# CCG2 register map
File version: 1.0
CPU: CM0 r1p0, little endian, no MPU, no FPU, 2 interrupt priority bits
Registers are 32-bit, read-write, reset 0x0 unless marked. A register's access mark holds for its fields unless they carry their own. Offsets are from the block's base; [hi:lo] are bit positions; <NAME> marks a mode.

## SCB0 (part 1 of 2)
Base 0x40050000
Same registers: SCB1 0x40060000
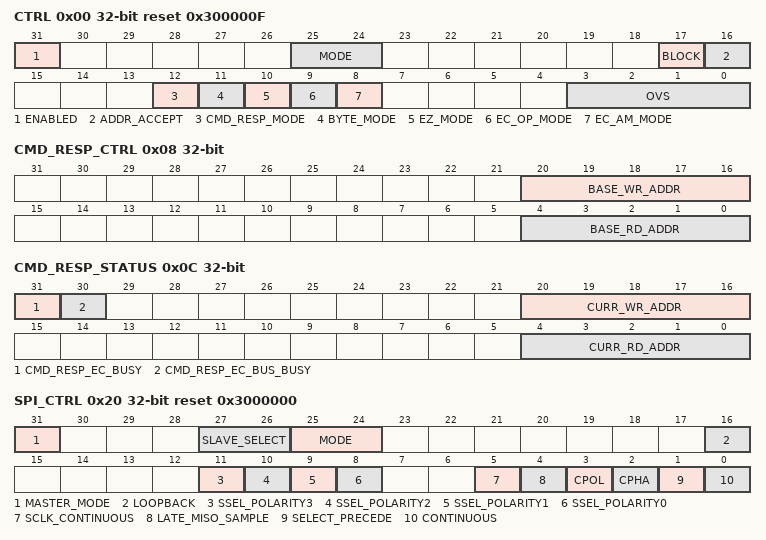
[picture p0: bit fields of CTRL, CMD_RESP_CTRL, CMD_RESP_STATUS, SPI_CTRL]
0x00 CTRL reset 0x300000F — Generic control register.
  [31] ENABLED — IP enabled ('1') or not ('0'). The proper order in which to initialize the IP is as follows: - Program protocol specific information using SPI_CTRL, UART_CTRL (and UART_TX_CTRL and UART_RX_CTRL) or I2C_CTRL. This includes selection of a submode, master/slave functionality and transmitter/receiver functionality when applicable. - Program generic transmitter (TX_CTRL) and receiver (RX_CTRL) information. This includes enabling of the transmitter and receiver functionality. - Program transmitter FIFO (TX_FIFO_CTRL) and receiver FIFO (RX_FIFO_CTRL) information. - Program CTRL to enable IP, select the specific operation mode and oversampling factor. When the IP is enabled, no control information should be changed. Changes should be made AFTER disabling the IP, e.g. to modify the operation mode (from I2C to SPI) or to go from externally to internally clocked. The change takes effect after the IP is re-enabled. Note that disabling the IP will cause re-initialization of the design and associated state is lost (e.g. FIFO content).
  [25:24] MODE — Mode of operation (3: Reserved)
    0=I2C; 1=SPI; 2=UART
  [17] BLOCK — Only used in externally clocked mode. If the externally clocked logic and the MMIO SW accesses to EZ memory coincide/collide, this bit determines whether a SW access should block and result in bus wait states ('BLOCK is 1') or not (BLOCK is '0'). IF BLOCK is �0� and the accesses collide, MMIO read operations return 0xffff:ffff and MMIO write operations are ignored. Colliding accesses are registered as interrupt causes: field BLOCKED of MMIO registers INTR_TX and INTR_RX.
  [16] ADDR_ACCEPT — Determines whether a received matching address is accepted in the RX FIFO ('1') or not ('0'). In I2C mode, this field is used to allow the slave to put the received slave address or general call address in the RX FIFO. Note that a received matching address is put in the RX FIFO when ADDR_ACCEPT is '1' for both I2C read and write transfers. In multi-processor UART receiver mode, this field is used to allow the receiver to put the received address in the RX FIFO. Note: non-matching addresses are never put in the RX FIFO.
  [12] CMD_RESP_MODE — Determines CMD_RESP mode of operation: '0': CMD_RESP mode disabled. '1': CMD_RESP mode enabled (also requires EC_AM_MODE and EC_OP_MODE to be set to '1').
  [11] BYTE_MODE — Determines the number of bits per FIFO data element: '0': 16-bit FIFO data elements. '1': 8-bit FIFO data elements. This mode doubles the amount of FIFO entries, but TX_CTRL.DATA_WIDTH and RX_CTRL.DATA_WIDTH are restricted to [0, 7].
  [10] EZ_MODE — Non EZ mode ('0') or EZ mode ('1'). In EZ mode, a meta protocol is applied to the serial interface protocol. This meta protocol adds meaning to the data frames transferred by the serial interface protocol: a data frame can represent a memory address, a write memory data element or a read memory data element. EZ mode is only used for synchronous serial interface protocols: SPI and I2C. In SPI mode, only Motorola submode (all Motorola modes: 0, 1, 2, 3) is supported and the transmitter should use continuous data frames; i.e. data frames mot seperated by slave deselection. This mode is only applicable to slave functionality. In EZ mode, the slave can read from and write to an addressable memory structure of 32 bytes. In EZ mode, data frames should 8-bit in size and should be transmitted and received with the Most Significant Bit (MSB) first. In UART mode this field should be '0'.
  [9] EC_OP_MODE — Internally clocked mode ('0') or externally clocked mode ('1') operation. In internally clocked mode, the serial interface protocols run off the peripheral clock. In externally clocked mode, the serial interface protocols run off the clock as provided by the serial interface. Externally clocked operation mode is only used for synchronous serial interface protocols (SPI and I2C) in slave mode AND EZ mode. In SPI mode, only Motorola submode (all Motorola modes: 0, 1, 2, 3) is supported. The maximum SPI slave, EZ mode bitrate is 48 Mbps (transmission and IO delays outside the IP will degrade the effective bitrate). In UART mode this field should be '0'.
  [8] EC_AM_MODE — Internally clocked mode ('0') or externally clocked mode ('1') address matching (I2C) or selection (SPI). In internally clocked mode, the serial interface protocols run off the peripheral clock. In externally clocked mode, the serial interface protocols run off the clock as provided by the serial interface. Externally clocked mode is only used for synchronous serial interface protocols (SPI and I2C) in slave mode. In SPI mode, only Motorola submode (all Motorola modes: 0, 1, 2, 3) is supported. In UART mode this field should be '0'.
  [3:0] OVS — Serial interface bit period oversampling factor expressed in lP clock cycles. Used for SPI and UART functionality. OVS + 1 IP clock cycles constitute a single serial interface clock/bit cycle. The IP clock is provided by the programmable clock IP. This field is NOT used in externally clocked mode. If OVS is odd, the oversampling factor is even and the first and second phase of the interface clock period are the same. If OVS is even, the oversampling factor is odd and the first phase of the interface clock period is 1 peripheral clock cycle longer than the second phase of the interface clock period. In SPI master mode, the valid range is [3, 15]. At an IP frequency of 48 MHz, the maximum IP bit rate is 12 Mbps. The effective system bit rate is dependent on the external SPI slave that we communicate with. If the SPI output clock "spi_clk_out" to SPI MISO input "spi_miso_in" round trip delay is introducing significant delays (multiple "spi_clk_out" cycles), it may be necessary to increase OVS and/or to set SPI_CTRL.LATE_MISO_SAMPLE to '1' to achieve the maximum possible system bit rate. The maximum IP bit rate of 12 Mbps provides an IP centric perspective, assuming ideal (0 ns) IO cell and routing (chip and board) delay. The required IP clock/IF clock ratio increases and the calculated maximum bit rate decreases, when realistic chip and routing delays are taken into account. In SPI slave mode, the OVS field is NOT used. However, there is a frequency requirement for the IP clock wrt. the interface (IF) clock to guarantee functional correct behavior. This requirement is expressed as a ratio: IP clock/IF clock. The ratio is dependent on the setting of RX_CTRL.MEDIAN and the external SPI master's capability to support "late MISO sample" functionality (similar to our SPI master functionality represented by SPI_CTRL.LATE_MISO_SAMPLE): - MEDIAN is '0' and external SPI master has NO "late MISO sample functionality": IP clock/IF clock >= 6. At a IP frequency of 48 MHz, the maximum bit rate is 8 Mbps. - MEDIAN is '0' and external SPI master has "late MISO sample functionality": IP clock/IF clock >= 3. At a IP frequency of 48 MHz, the maximum bit rate is 16 Mbps. - MEDIAN is '1' and external SPI master has NO "late MISO sample functionality": IP clock/IF clock >= 8. At a IP frequency of 48 MHz, the maximum bit rate is 6 Mbps. - MEDIAN is '1' and external SPI master has "late MISO sample functionality": IP clock/IF clock >= 4. At a IP frequency of 48 MHz, the maximum bit rate is 12 Mbps. The maximum bit rates provide an IP centric perspective, assuming ideal (0 ns) IO cell and routing (chip and board) delay. The required IP clock/IF clock ratio increases and the calculated maximum bit rate decreases, when realistic chip and routing delays are taken into account. In UART standard submode (including LIN), the valid range is [7, 15]. In UART SmartCard submode, the valid range is [7, 15]. In UART TX IrDA submode this field indirectly specifies the oversampling. The oversampling determines the interface clock/bit cycle and the width of the pulse. Only normal transmission mode is supported, the pulse is roughly 3/16 of the bit period (for all bit rates). There is only one valid OVS value: - 0: 16 times oversampling. IP clock frequency of 16*115.2 KHz for 115.2 Kbps. IP clock frequency of 16*57.6 KHz for 57.6 Kbps. IP clock frequency of 16*38.4 KHz for 38.4 Kbps. IP clock frequency of 16*19.2 KHz for 19.2 Kbps. IP clock frequency of 16*9.6 KHz for 9.6 Kbps. IP clock frequency of 16*2.4 KHz for 2.4 Kbps. IP clock frequency of 16*1.2 KHz for 1.2 Kbps. - all other values are not used in normal mode. In UART RX IrDA submode (1.2, 2.4, 9.6, 19.2, 38.4, 57.6 and 115.2 Kbps) this field indirectly specifies the oversampling. The oversampling determines the interface clock/bit cycle and the width of the pulse. In normal transmission mode, this pulse is roughly 3/16 of the bit period (for all bit rates). In low power transmission mode, this pulse is potentially smaller (down to 1.62 us typical and 1.41 us minimal) than 3/16 of the bit period (for < 115.2 Kbps bitrates). Pulse widths greater or equal than two IP clock cycles are guaranteed to be detected by the receiver. Pulse widths less than two IP clock cycles and greater or equal than one IP clock cycle may be detected by the receiver. Pulse widths less than one IP clock cycle will not be detected by the receiver. RX_CTRL.MEDIAN should be set to '1' for IrDA receiver functionality. The IP clock (as provided by the programmable clock IP) and the oversampling together determine the IrDA bitrate. Normal mode, OVS field values (with the required IP clock frequency): - 0: 16 times oversampling. IP clock frequency of 16*115.2 KHz for 115.2 Kbps. IP clock frequency of 16*57.6 KHz for 57.6 Kbps. IP clock frequency of 16*38.4 KHz for 38.4 Kbps. IP clock frequency of 16*19.2 KHz for 19.2 Kbps. IP clock frequency of 16*9.6 KHz for 9.6 Kbps. IP clock frequency of 16*2.4 KHz for 2.4 Kbps. IP clock frequency of 16*1.2 KHz for 1.2 Kbps. - all other values are not used in normal mode. Low power mode, OVS field values (with the required IP clock frequency): - 0: 16 times oversampling. IP clock frequency of 16*115.2 KHz for 115.2 Kbps. - 1: 32 times oversampling. IP clock frequency of 32*57.6 KHz for 57.6 Kbps. - 2: 48 times oversampling. IP clock frequency of 48*38.4 KHz for 38.4 Kbps. - 3: 96 times oversampling. IP clock frequency of 96*19.2 KHz for 19.2 Kbps. - 4: 192 times oversampling. IP clock frequency of 192*9.6 KHz for 9.6 Kbps. - 5: 768 times oversampling. IP clock frequency of 768*2.4 KHz for 2.4 Kbps. - 6: 1536 times oversampling. IP clock frequency of 1536*1.2 KHz for 1.2 Kbps. - all other values are not used in low power mode.
0x04 STATUS reset not defined — Generic status register.
  [0] EC_BUSY ro — Inidicates whether the externally clocked logic is potentially accessing the EZ memory (this is only possible in EZ mode). This bit can be used by SW to determine whether it is safe to issue a SW access to the EZ memory (without bus wait states (a blocked SW access) or bus errors being generated). Note that the INTR_TX.BLOCKED and INTR_RX.BLOCKED interrupt causes are used to indicate whether a SW access was actually blocked by externally clocked logic.
0x08 CMD_RESP_CTRL — Command/response control register.
  [20:16] BASE_WR_ADDR — I2C/SPI read base address for CMD_RESP mode. Address is used by a I2C CMD_RESP mode write transfer (CTRL.MODE is I2C) or a SPI CMD_RESP mode write transfer (CTRL.MODE is SPI): at the start of a write transfer BASE_WE_ADDR is copied to CMD_RESP_STATUS.CURR_WR_ADDR. This field should not be modified during ongoing bus transfers.
  [4:0] BASE_RD_ADDR — I2C/SPI read base address for CMD_RESP mode. Address is used by a I2C CMD_RESP mode read transfer (CTRL.MODE is I2C) or a SPI CMD_RESP mode read transfer (CTRL.MODE is SPI): at the start of a read transfer BASE_RD_ADDR is copied to CMD_RESP_STATUS.CURR_RD_ADDR. This field should not be modified during ongoing bus transfers.
0x0C CMD_RESP_STATUS reset not defined — Command/response status register. The register fields reflect register states without a default/reset value (CURR_RD_ADDR and CURR_WR_ADDR) or reflect an external bus state. Therefore, these registers are undefined after the IP is enabled.
  [31] CMD_RESP_EC_BUSY ro — Indicates whether the CURR_RD_ADDR and CURR_WR_ADDR fields in this register are reliable (CMD_RESP_EC_BUSY is '0') or not reliable (CMD_RESP_EC_BUSY is '1'). Note: - When there is no bus transfer, CMD_RESP_EC_BUSY is '0'. - When there is a bus transfer, CMD_RESP_EC_BUSY is '0', when the CURR_RD_ADDR and CURR_WR_ADDR are not updated by the HW. - When there is a bus transfer, CMD_RESP_EC_BUSY is '1', when the CURR_RD_ADDR or CURR_WR_ADDR are updated by the HW. Note that this update lasts a single serial interface clock cycle.
  [30] CMD_RESP_EC_BUS_BUSY ro — Indicates whether there is an ongoing bus transfer to the IP. '0': no ongoing bus transfer. '1': ongoing bus transferr. For SPI, the field is '1' when the slave is selected. For I2C, the field is set to '1' at a I2C START/RESTART. In case of an address match, the field is set to '0' on a I2C STOP. In case of NO address match, the field is set to '0' after the failing address match.
  [20:16] CURR_WR_ADDR ro — I2C/SPI write current address for CMD_RESP mode. HW increments the field after a read access to the memory buffer. However, when the last memory buffer address is reached, the address is NOT incremented (but remains at the maximim memory buffer address). The field is used to determine how many bytes have been written (# bytes = CURR_WR_ADDR - CMD_RESP_CTRL.BASE_WR_ADDR). This field is reliable during when there is no bus transfer. This field is potentially unreliable when there is a bus transfer bus transfer: when CMD_RESP_EC_BUSY is '0', the field is reliable.
  [4:0] CURR_RD_ADDR ro — I2C/SPI read current address for CMD_RESP mode. HW increments the field after a read access to the memory buffer. However, when the last memory buffer address is reached, the address is NOT incremented (but remains at the maximim memory buffer address). The field is used to determine how many bytes have been read (# bytes = CURR_RD_ADDR - CMD_RESP_CTRL.BASE_RD_ADDR). This field is reliable during when there is no bus transfer. This field is potentially unreliable when there is a bus transfer bus transfer: when CMD_RESP_EC_BUSY is '0', the field is reliable.
0x20 SPI_CTRL reset 0x3000000 — SPI control register.
  [31] MASTER_MODE — Master ('1') or slave ('0') mode. In master mode, transmission will commence on availability of data frames in the TX FIFO. In slave mode, when selected and there is no data frame in the TX FIFO, the slave will transmit all '1's. In both master and slave modes, received data frames will be lost if the RX FIFO is full.
  [27:26] SLAVE_SELECT — Selects one of the four outgoing SPI slave select signals: - 0: Slave 0, SPI_SELECT[0]. - 1: Slave 1, SPI_SELECT[1]. - 2: Slave 2, SPI_SELECT[2]. - 3: Slave 3, SPI_SELECT[3]. Only used in master mode. The IP should be disabled when changes are made to this field.
  [25:24] MODE — Submode of SPI operation (3: Reserved).
    0=SPI_MOTOROLA; 1=SPI_TI; 2=SPI_NS
  [16] LOOPBACK — Local loopback control (does NOT affect the information on the pins). Only used in master mode. Not used in National Semiconductors submode. '0': the SPI master MISO line "spi_miso_in" is connected to the SPI MISO pin. '1': the SPI master MISO line "spi_miso_in" is connected to the SPI master MOSI line "spi_mosi_out". In other words, in loopback mode the SPI master receives on MISO what it transmits on MOSI.
  [11] SSEL_POLARITY3 — Slave select polarity. SSEL_POLARITY3 applies to the outgoing SPI slave select signal 3 (master mode).
  [10] SSEL_POLARITY2 — Slave select polarity. SSEL_POLARITY2 applies to the outgoing SPI slave select signal 2 (master mode).
  [9] SSEL_POLARITY1 — Slave select polarity. SSEL_POLARITY1 applies to the outgoing SPI slave select signal 1 (master mode).
  [8] SSEL_POLARITY0 — Slave select polarity. SSEL_POLARITY0 applies to the outgoing SPI slave select signal 0 (master mode) and to the incoming SPI slave select signal (slave mode). For Motorola and National Semiconductors submodes: '0': slave select is low/'0' active. '1': slave select is high/'1' active. For Texas Istruments submode: '0': high/'1' active precede/coincide pulse. '1': low/'0' active precede/coincide pulse.
  [5] SCLK_CONTINUOUS — Only applicable in master mode. '0': SCLK is generated, when the SPI master is enabled and data is transmitted. '1': SCLK is generated, when the SPI master is enabled. This mode is useful for slave devices that use SCLK for functional operation other than just SPI functionality.
  [4] LATE_MISO_SAMPLE — Changes the SCLK edge on which MISO is captured. Only used in master mode. When '0', the default applies (for Motorola as determined by CPOL and CPHA, for Texas Instruments on the falling edge of SCLK and for National Semiconductors on the rising edge of SCLK). When '1', the alternate clock edge is used (which comes half a SPI SCLK period later). Late sampling addresses the round trip delay associated with transmitting SCLK from the master to the slave and transmitting MISO from the slave to the master.
  [3] CPOL — Indicates the clock polarity. Only used in SPI Motorola submode. This field, together with the CPHA field, indicates when MOSI data is driven and MISO data is captured: - CPOL is �0�: SCLK is �0� when not transmitting data. - CPOL is �1�: SCLK is �1� when not transmitting data.
  [2] CPHA — Only applicable in SPI Motorola submode. Indicates the clock phase. This field, together with the CPOL field, indicates when MOSI data is driven and MISO data is captured: - Motorola mode 0. CPOL is �0�, CPHA is �0�: MOSI is driven on a falling edge of SCLK. MISO is captured on a rising edge of SCLK. - Motorola mode 1. CPOL is �0�, CPHA is �1�: MOSI is driven on a rising edge of SCLK. MISO is captured on a falling edge of SCLK. - Motorola mode 2. CPOL is �1�, CPHA is �0�: MOSI is driven on a rising edge of SCLK. MISO is captured on a falling edge of SCLK. - Motorola mode 3. CPOL is �1�, CPHA is �1�: MOSI is driven on a falling edge of SCLK. MISO is captured on a rising edge of SCLK.
  [1] SELECT_PRECEDE — Only used in SPI Texas Instruments' submode. When '1', the data frame start indication is a pulse on the SELECT line that precedes the transfer of the first data frame bit. When '0', the data frame start indication is a pulse on the SELECT line that coincides with the transfer of the first data frame bit.
  [0] CONTINUOUS — Continuous SPI data transfers enabled ('1') or not ('0'). This field is used in master mode. In slave mode, both continuous and non-continuous SPI data transfers are supported independent of this field. When continuous transfers are enabled individual data frame transfers are not necessarily seperated by slave deselection (as indicated by the level or pulse on the SELECT line): if the TX FIFO has multiple data frames, data frames are send out without slave deselection. When continuous transfers are not enabled individual data frame transfers are always seperated by slave deselection: independent of the availability of TX FIFO data frames, data+G65 frames are send out with slave deselection.
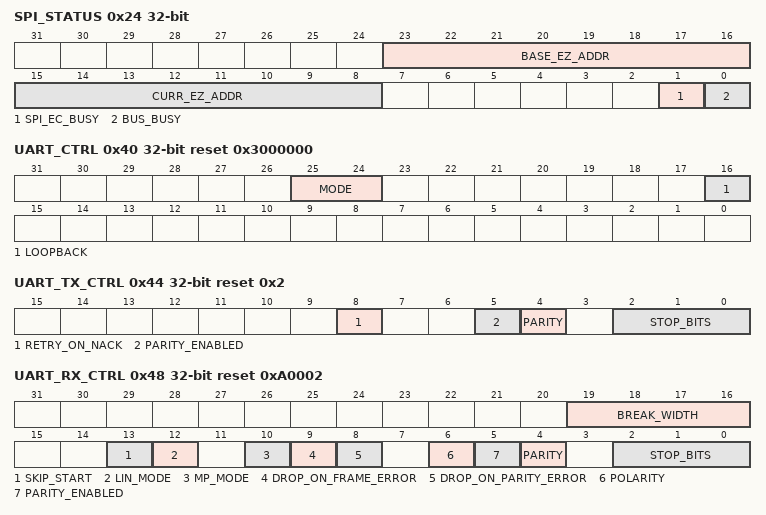
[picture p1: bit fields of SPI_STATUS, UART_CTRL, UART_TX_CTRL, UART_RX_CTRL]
0x24 SPI_STATUS reset not defined
  [23:16] BASE_EZ_ADDR ro — SPI base EZ address. Address as provided by a SPI write transfer. This field is only reliable in internally clocked mode. In externally clocked mode the field may be unreliable, as clock domain synchronization is not performed in the design.
  [15:8] CURR_EZ_ADDR ro — SPI current EZ address. Current address pointer. This field is only reliable in internally clocked mode. In externally clocked mode the field may be unreliable (during an ongoing transfer when SPI_EC_BUSY is '1'), as clock domain synchronization is not performed in the design.
  [1] SPI_EC_BUSY ro — Inidicates whether the externally clocked logic is potentially accessing the EZ memory and/or updating BASE_ADDR or CURR_ADDR (this is only possible in EZ mode). This bit can be used by SW to determine whether BASE_ADDR and CURR_ADDR are reliable.
  [0] BUS_BUSY ro — SPI bus is busy. The bus is considered busy ('1') during an ongoing transaction. For Motorola and National submodes, the busy bit is '1', when the slave selection (low active) is activated. For TI submode, the busy bit is '1' from the time the preceding/coinciding slave select (high active) is activated for the first transmitted data frame, till the last MOSI/MISO bit of the last data frame is transmitted.
0x40 UART_CTRL reset 0x3000000 — UART control register.
  [25:24] MODE — Submode of UART operation (3: Reserved)
    0=UART_STD; 1=UART_SMARTCARD; 2=UART_IRDA
  [16] LOOPBACK — Local loopback control (does NOT affect the information on the pins). When '0', the transmitter TX line "uart_tx_out" is connected to the TX pin and the receiver RX line "uart_rx_in" is connected to the RX pin. When '1', the transmitter TX line "uart_tx_out" is connected to the receiver RX line "uart_rx_in". A similar connections scheme is followed for "uart_rts_out" and "uart_cts_in". This allows a SCB UART transmitter to communicate with its receiver counterpart.
0x44 UART_TX_CTRL reset 0x2 — UART transmitter control register.
  [8] RETRY_ON_NACK — When '1', a data frame is retransmitted when a negative acknowledgement is received. Only applicable to the SmartCard submode.
  [5] PARITY_ENABLED — Parity generation enabled ('1') or not ('0'). Only applicable in standard UART submodes. In SmartCard submode, parity generation is always enabled through hardware. In IrDA submode, parity generation is always disabled through hardware
  [4] PARITY — Parity bit. When '0', the transmitter generates an even parity. When '1', the transmitter generates an odd parity. Only applicable in standard UART and SmartCard submodes.
  [2:0] STOP_BITS — Stop bits. STOP_BITS + 1 is the duration of the stop period in terms of halve bit periods. Valid range is [1, 7]; i.e. a stop period should last at least one bit period.
0x48 UART_RX_CTRL reset 0xA0002 — UART receiver control register.
  [19:16] BREAK_WIDTH — Break width. BREAK_WIDTH + 1 is the minimum width in bit periods of a break. During a break the transmitted/received line value is '0'. This feature is useful for standard UART submode and LIN submode ("break field" detection). Once, the break is detected, the INTR_RX.BREAK_DETECT bit is set to '1'. Note that break detection precedes baud rate detection, which is used to synchronize/refine the receiver clock to the transmitter clock. As a result, break detection operates with an unsynchronized/unrefined receiver clock. Therefore, the receiver's definition of a bit period is imprecise and the setting of this field should take this imprecision into account. The LIN standard also accounts for this imprecision: a LIN start bit followed by 8 data bits allows for up to 9 consecutive '0' bit periods during regular transmission, whereas the LIN break detection should be at least 13 consecutive '0' bit periods. This provides for a margin of 4 bit periods. Therefore, the default value of this field is set to 10, representing a minimal break field with of 10+1 = 11 bit periods; a value in between the 9 consecutive bit periods of a regular transmission and the 13 consecutive bit periods of a break field. This provides for slight imprecisions of the receiver clock wrt. the transmitter clock. There should not be a need to program this field to any value other than its default value.
  [13] SKIP_START — Only applicable in standard UART submode. When '1', the receiver skips start bit detection for the first received data frame. Instead, it synchronizes on the first received data frame bit, which should be a '1'. This functionality is intended for wake up from DeepSleep when receiving a data frame. The transition from idle ('1') to START ('0') on the RX line is used to wake up the CPU. The transition detection (and the associated wake up functionality) is performed by the GPIO2 IP. The woken up CPU will enable the SCB's UART receiver functionality. Once enabled, it is assumed that the START bit is ongoing (the CPU wakeup and SCB enable time should be less than the START bit period). The SCB will synchronize to a '0' to '1' transition, which indicates the first data frame bit is received (first data frame bit should be '1'). After synchronization to the first data frame bit, the SCB will resume normal UART functionality: subsequent data frames will be synchronized on the receipt of a START bit.
  [12] LIN_MODE — Only applicable in standard UART submode. When '1', the receiver performs break detection and baud rate detection on the incoming data. First, break detection counts the amount of bit periods that have a line value of '0'. BREAK_WIDTH specifies the minum required amount of bit periods. Successful break detection sets the INTR_RX.BREAK_DETECT interrupt cause to '1'. Second, baud rate detection counts the amount of peripheral clock periods that are use to receive the synchronization byte (0x55; least significant bit first). The count is available through UART_RX_STATUS.BR_COUNTER. Successful baud rate detection sets the INTR_RX.BAUD_DETECT interrupt cause to '1' (BR_COUNTER is reliable). This functionality is used to synchronize/refine the receiver clock to the transmitter clock. The receiver software can use the BR_COUNTER value to set the right IP clock (from the programmable clock IP) to guarantee successful receipt of the first LIN data frame (Protected Identifier Field) after the synchronization byte.
  [10] MP_MODE — Multi-processor mode. When '1', multi-processor mode is enabled. In this mode, RX_CTRL.DATA_WIDTH should indicate a 9-bit data frame. In multi-processor mode, the 9th received bit of a data frame seperates addresses (bit is '1') from data (bit is '0'). A received address is matched with RX_MATCH.DATA and RX_MATCH.MASK. In the case of a match, subsequent received data are sent to the RX FIFO. In the case of NO match, subsequent received data are dropped.
  [9] DROP_ON_FRAME_ERROR — Behaviour when an error is detected in a start or stop period. When '0', received data is send to the RX FIFO. When '1', received data is dropped and lost.
  [8] DROP_ON_PARITY_ERROR — Behaviour when a parity check fails. When '0', received data is send to the RX FIFO. When '1', received data is dropped and lost. Only applicable in standard UART and SmartCard submodes (negatively acknowledged SmartCard data frames may be dropped with this field).
  [6] POLARITY — Inverts incoming RX line signal "uart_rx_in". Inversion is after local loopback. This functionality is intended for IrDA receiver functionality.
  [5] PARITY_ENABLED — Parity checking enabled ('1') or not ('0'). Only applicable in standard UART submode. In SmartCard submode, parity checking is always enabled through hardware. In IrDA submode, parity checking is always disabled through hardware.
  [4] PARITY — Parity bit. When '0', the receiver expects an even parity. When '1', the receiver expects an odd parity. Only applicable in standard UART and SmartCard submodes.
  [2:0] STOP_BITS — Stop bits. STOP_BITS + 1 is the duration of the stop period in terms of halve bit periods. Valid range is [1, 7]; i.e. a stop period should last at least one bit period. If STOP_BITS is '1', stop bits error detection is NOT performed. If STOP_BITS is in [2, 7], stop bits error detection is performed and the associated interrupt cause INTR_RX.FRAME_ERROR is set to '1' if an error is detected. In other words, the receiver supports data frames with a 1 bit period stop bit sequence, but requires at least 1.5 bit period stop bit sequences to detect errors. This limitation is due to possible transmitter and receiver clock skew that prevents the design from doing reliable stop bit detection for short (1 bit bit period) stop bit sequences. Note that in case of a stop bits error, the successive data frames may get lost as the receiver needs to resynchronize its start bit detection. The amount of lost data frames depends on both the amount of stop bits, the idle ('1') time between data frames and the data frame value.
0x4C UART_RX_STATUS reset not defined — UART receiver status register.
  [11:0] BR_COUNTER ro — Amount of peripheral clock periods that constitute the transmission of a 0x55 data frame (sent least signficant bit first) as determined by the receiver. BR_COUNTER / 8 is the amount of peripheral clock periods that constitute a bit period. This field has valid data when INTR_RX.BAUD_DETECT is set to '1'.
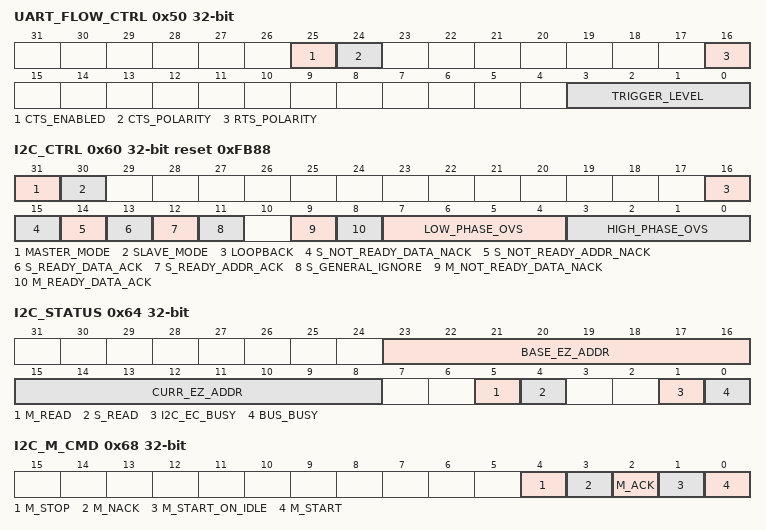
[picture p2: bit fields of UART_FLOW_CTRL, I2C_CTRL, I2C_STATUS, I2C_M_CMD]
0x50 UART_FLOW_CTRL — UART flow control register UART flow control is a design time configuration parameter, which make the presence of this MMIO register conditional to the configuration. The "uart_rts_out" and "uart_cts_in" are always present on the IP interface. If flow control is configured out, "uart_rts_out" is NOT connected, and "uart_cts_in" should be connected to '0'.
  [25] CTS_ENABLED — Enable use of CTS input signal "uart_cts_in" by the UART transmitter: '0': Disabled. The UART transmitter ignores "uart_cts_in", and transmits when a data frame is available for transmission in the TX FIFO or the TX shift register. '1': Enabled. The UART transmitter uses "uart_cts_in" to qualify the transmission of data. It transmits when "uart_cts_in" is active and a data frame is available for transmission in the TX FIFO or the TX shift register. If UART_CTRL.LOOPBACK is '1', "uart_cts_in" is connected to "uart_rts_out" in the IP (both signals are subjected to signal polarity changes are indicated by RTS_POLARITY and CTS_POLARITY).
  [24] CTS_POLARITY — Polarity of the CTS input signal "uart_cts_in": '0': CTS is low/'0' active; "uart_cts_in" is '0' when active and "uart_cts_in" is '1' when inactive. '1': CTS is high/'1' active; "uart_cts_in" is '1' when active and "uart_cts_in" is '0' when inactive.
  [16] RTS_POLARITY — Polarity of the RTS output signal "uart_rts_out": '0': RTS is low/'0' active; "uart_rts_out" is '0' when active and "uart_rts_out" is '1' when inactive. '1': RTS is high/'1' active; "uart_rts_out" is '1' when active and "uart_rts_out" is '0' when inactive. During IP reset (Hibernate system power mode), "uart_rts_out" is '1'. This represents an inactive state assuming a low/'0' active polarity.
  [3:0] TRIGGER_LEVEL — Trigger level. When the receiver FIFO has less entries than the amount of this field, a Ready To Send (RTS) output signal "uart_rts_out" is activated. By setting this field to "0", flow control is effectively SW disabled (may be useful for debug purposes).
0x60 I2C_CTRL reset 0xFB88 — I2C control register.
  [31] MASTER_MODE — Master mode enabled ('1') or not ('0'). Note that both master and slave modes can be enabled at the same time. This allows the IP to address itself.
  [30] SLAVE_MODE — Slave mode enabled ('1') or not ('0').
  [16] LOOPBACK — Local loopback control (does NOT affect the information on the pins). Only applicable in master/slave mode. When '0', the I2C SCL and SDA lines are connected to the I2C SCL and SDA pins. When '1', I2C SCL and SDA lines are routed internally in the peripheral, and as a result unaffected by other I2C devices. This allows a SCB I2C peripheral to address itself.
  [15] S_NOT_READY_DATA_NACK — For internally clocked logic only. Only used when: - non EZ mode. Functionality is as follows: - 1: a received data element byte the slave is immediately NACK'd when the receiver FIFO is full. - 0: clock stretching is performed (till the receiver FIFO is no longer full).
  [14] S_NOT_READY_ADDR_NACK — For internally clocked logic (EC_AM is '0' and EC_OP is '0') on an address match or general call address (and S_GENERAL_IGNORE is '0'). Only used when: - EC_AM is '0', EC_OP is '0' and non EZ mode. Functionality is as follows: - 1: a received (matching) slave address is immediately NACK'd when the receiver FIFO is full. - 0: clock stretching is performed (till the receiver FIFO is no longer full). For externally clocked logic (EC_AM is '1') on an address match or general call address (and S_GENERAL_IGNORE is '0'). Only used when (NOT used when EC_AM is '1' and EC_OP is '1' and address match and EZ mode): - EC_AM is '1' and EC_OP is '0'. - EC_AM is '1' and general call address match. - EC_AM is '1' and non EZ mode. Functionality is as follows: - 1: a received (matching or general) slave address is always immediately NACK'd. There are two possibilities: 1). the internally clocked logic is enabled (we are in Active system power mode) and it handles the rest of the current transfer. In this case the I2C master will not observe the NACK. 2). the internally clocked logic is not enabled (we are in DeepSleep system power mode). In this case the I2C master will observe the NACK and may retry the transfer in the future (which gives the internally clocked logic the time to wake up from DeepSleep system power mode). - 0: clock stretching is performed (till the internally clocked logic takes over). The internally clocked logic will handle the ongoing transfer as soon as it is enabled.
  [13] S_READY_DATA_ACK — When '1', a received data element by the slave is immediately ACK'd when the receiver FIFO is not full. In EZ mode, this field should be set to '1'.
  [12] S_READY_ADDR_ACK — When '1', a received (matching) slave address is immediately ACK'd when the receiver FIFO is not full. In EZ mode, this field should be set to '1'.
  [11] S_GENERAL_IGNORE — When '1', a received general call slave address is immediately NACK'd (no ACK or clock stretching) and treated as a non matching slave address. This is useful for slaves that do not need any data supplied within the general call structure.
  [9] M_NOT_READY_DATA_NACK — When '1', a received data element byte the master is immediately NACK'd when the receiver FIFO is full. When '0', clock stretching is used instead (till the receiver FIFO is no longer full).
  [8] M_READY_DATA_ACK — When '1', a received data element by the master is immediately ACK'd when the receiver FIFO is not full.
  [7:4] LOW_PHASE_OVS — Serial I2C interface low phase oversampling factor. LOW_PHASE_OVS + 1 peripheral clock periods constitute the low phase of a bit period. The valid range is [7, 15] with input signal median filtering and [6, 15] without input signal median filtering. The field is only used in master mode. In slave mode, the field is NOT used. However, there is a frequency requirement for the IP clock wrt. the regular (no stretching) interface (IF) low time to guarantee functional correct behavior. With input signal median filtering, the IF low time should be >= 8 IP clock cycles and <= 16 IP clock cycles. Without input signal median filtering, the IF low time should be >= 7 IP clock cycles and <= 16 IP clock cycles.
  [3:0] HIGH_PHASE_OVS — Serial I2C interface high phase oversampling factor. HIGH_PHASE_OVS + 1 peripheral clock periods constitute the high phase of a bit period. The valid range is [5, 15] with input signal median filtering and [4, 15] without input signal median filtering. The field is only used in master mode. In slave mode, the field is NOT used. However, there is a frequency requirement for the IP clock wrt. the regular interface (IF) high time to guarantee functional correct behavior. With input signal median filtering, the IF high time should be >= 6 IP clock cycles and <= 16 IP clock cycles. Without input signal median filtering, the IF high time should be >= 5 IP clock cycles and <= 16 IP clock cycles.
0x64 I2C_STATUS (reset mask 0x31)
  [23:16] BASE_EZ_ADDR ro — I2C slave base EZ address. Address as provided by an I2C write transfer. This field is only reliable in internally clocked mode. In externally clocked mode the field may be unreliable, as clock domain synchronization is not performed in the design.
  [15:8] CURR_EZ_ADDR ro — I2C slave current EZ address. Current address pointer. This field is only reliable in internally clocked mode. In externally clocked mode the field may be unreliable (during an ongoing transfer when I2C_EC_BUSY is '1'), as clock domain synchronization is not performed in the design.
  [5] M_READ ro — I2C master read transfer ('1') or I2C master write transfer ('0'). When the I2C master is inactive/idle or transmitting START, REPEATED START, STOP or an address, this field is '0''.
  [4] S_READ ro — I2C slave read transfer ('1') or I2C slave write transfer ('0'). When the I2C slave is inactive/idle or receiving START, REPEATED START, STOP or an address, this field is '0''.
  [1] I2C_EC_BUSY ro — Inidicates whether the externally clocked logic is potentially accessing the EZ memory and/or updating BASE_ADDR or CURR_ADDR (this is only possible in EZ mode). This bit can be used by SW to determine whether BASE_ADDR and CURR_ADDR are reliable.
  [0] BUS_BUSY ro — I2C bus is busy. The bus is considered busy ('1'), from the time a START is detected or from the time the SCL line is '0'. The bus is considered idle ('0'), from the time a STOP is detected. If the IP is disabled, BUS_BUSY is '0'. After enabling the IP, it takes time for the BUS_BUSY to detect a busy bus. This time is the maximum high time of the SCL line. For a 100 kHz interface frequency, this maximum high time may last roughly 5 us (half a bit period). For single master systems, BUS_BUSY does not have to be used to detect an idle bus before a master starts a transfer using I2C_M_CMD.M_START (no bus collisions). For multi-master systems, BUS_BUSY can be used to detect an idle bus before a master starts a transfer using I2C_M_CMD.M_START_ON_IDLE (to prevent bus collisions).
0x68 I2C_M_CMD — I2C master command register. The register fields are not retained. This is to ensure that they come up as '0' after coming out of DeepSleep system power mode.
  [4] M_STOP — When '1', attempt to transmit a STOP. When this action is performed, the hardware sets this field to '0'. This command has a higher priority than I2C_M_CMD.M_START: in situations where both a STOP and a REPEATED START could be transmitted, M_STOP takes precedence over M_START.
  [3] M_NACK — When '1', attempt to transmit a negative acknowledgement (NACK). When this action is performed, the hardware sets this field to '0'.
  [2] M_ACK — When '1', attempt to transmit an acknowledgement (ACK). When this action is performed, the hardware sets this field to '0'.
  [1] M_START_ON_IDLE — When '1', transmit a START as soon as the bus is idle (I2C_STATUS.BUS_BUSY is '0', note that BUSY has a default value of '0'). For bus idle detection the hardware relies on STOP detection. As a result, bus idle detection is only functional after at least one I2C bus transfer has been detected on the bus (default/reset value of BUSY is '0') . A START is only transmitted when the master state machine is in the default state. When this action is performed, the hardware sets this field to '0'.
  [0] M_START — When '1', transmit a START or REPEATED START. Whether a START or REPEATED START is transmitted depends on the state of the master state machine. A START is only transmitted when the master state machine is in the default state. A REPEATED START is transmitted when the master state machine is not in the default state, but is working on an ongoing transaction. The REPEATED START can only be transmitted after a NACK or ACK has been received for a transmitted data element or after a NACK has been transmitted for a received data element. When this action is performed, the hardware sets this field to '0'.
